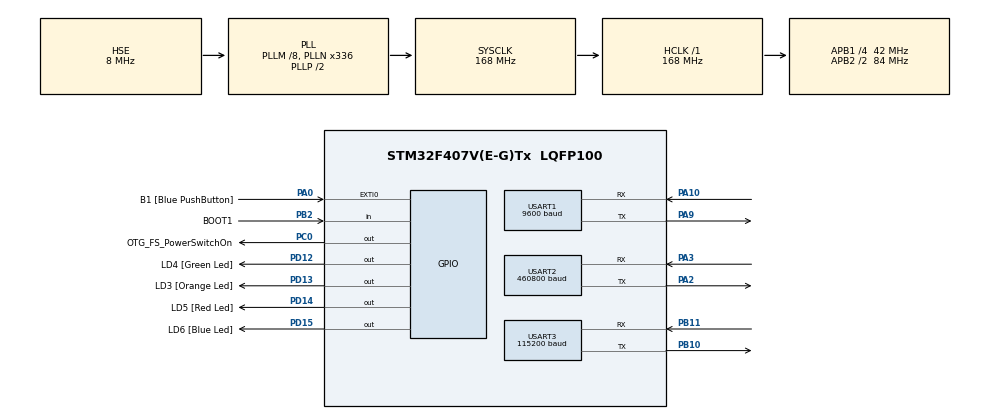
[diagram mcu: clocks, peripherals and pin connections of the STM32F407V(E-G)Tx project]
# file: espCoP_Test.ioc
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Dma.Request0=USART3_RX
Dma.Request1=USART3_TX
Dma.Request2=USART2_TX
Dma.Request3=USART1_RX
Dma.Request4=USART1_TX
Dma.USART1_RX.3.Direction=DMA_PERIPH_TO_MEMORY
Dma.USART1_RX.3.FIFOMode=DMA_FIFOMODE_DISABLE
Dma.USART1_RX.3.Instance=DMA2_Stream2
Dma.USART1_RX.3.MemDataAlignment=DMA_MDATAALIGN_BYTE
Dma.USART1_RX.3.MemInc=DMA_MINC_ENABLE
Dma.USART1_RX.3.Mode=DMA_NORMAL
Dma.USART1_RX.3.PeriphDataAlignment=DMA_PDATAALIGN_BYTE
Dma.USART1_RX.3.PeriphInc=DMA_PINC_DISABLE
Dma.USART1_RX.3.Priority=DMA_PRIORITY_LOW
Dma.USART1_TX.4.Direction=DMA_MEMORY_TO_PERIPH
Dma.USART1_TX.4.FIFOMode=DMA_FIFOMODE_DISABLE
Dma.USART1_TX.4.Instance=DMA2_Stream7
Dma.USART1_TX.4.MemDataAlignment=DMA_MDATAALIGN_BYTE
Dma.USART1_TX.4.MemInc=DMA_MINC_ENABLE
Dma.USART1_TX.4.Mode=DMA_NORMAL
Dma.USART1_TX.4.PeriphDataAlignment=DMA_PDATAALIGN_BYTE
Dma.USART1_TX.4.PeriphInc=DMA_PINC_DISABLE
Dma.USART1_TX.4.Priority=DMA_PRIORITY_LOW
Dma.USART2_TX.2.Direction=DMA_MEMORY_TO_PERIPH
Dma.USART2_TX.2.FIFOMode=DMA_FIFOMODE_DISABLE
Dma.USART2_TX.2.Instance=DMA1_Stream6
Dma.USART2_TX.2.MemDataAlignment=DMA_MDATAALIGN_BYTE
Dma.USART2_TX.2.MemInc=DMA_MINC_ENABLE
Dma.USART2_TX.2.Mode=DMA_NORMAL
Dma.USART2_TX.2.PeriphDataAlignment=DMA_PDATAALIGN_BYTE
Dma.USART2_TX.2.PeriphInc=DMA_PINC_DISABLE
Dma.USART2_TX.2.Priority=DMA_PRIORITY_LOW
Dma.USART3_RX.0.Direction=DMA_PERIPH_TO_MEMORY
Dma.USART3_RX.0.FIFOMode=DMA_FIFOMODE_DISABLE
Dma.USART3_RX.0.Instance=DMA1_Stream1
Dma.USART3_RX.0.MemDataAlignment=DMA_MDATAALIGN_BYTE
Dma.USART3_RX.0.MemInc=DMA_MINC_ENABLE
Dma.USART3_RX.0.Mode=DMA_NORMAL
Dma.USART3_RX.0.PeriphDataAlignment=DMA_PDATAALIGN_BYTE
Dma.USART3_RX.0.PeriphInc=DMA_PINC_DISABLE
Dma.USART3_RX.0.Priority=DMA_PRIORITY_LOW
Dma.USART3_TX.1.Direction=DMA_MEMORY_TO_PERIPH
Dma.USART3_TX.1.FIFOMode=DMA_FIFOMODE_DISABLE
Dma.USART3_TX.1.Instance=DMA1_Stream3
Dma.USART3_TX.1.MemDataAlignment=DMA_MDATAALIGN_BYTE
Dma.USART3_TX.1.MemInc=DMA_MINC_ENABLE
Dma.USART3_TX.1.Mode=DMA_NORMAL
Dma.USART3_TX.1.PeriphDataAlignment=DMA_PDATAALIGN_BYTE
Dma.USART3_TX.1.PeriphInc=DMA_PINC_DISABLE
Dma.USART3_TX.1.Priority=DMA_PRIORITY_LOW
Mcu.Family=STM32F4
Mcu.Name=STM32F407V(E-G)Tx
Mcu.Package=LQFP100
NVIC.DMA1_Stream1_IRQn=true\:0\:0\:false\:false\:true\:false
NVIC.DMA1_Stream3_IRQn=true\:0\:0\:false\:false\:true\:false
NVIC.DMA1_Stream6_IRQn=true\:0\:0\:false\:false\:true\:false
NVIC.DMA2_Stream2_IRQn=true\:0\:0\:false\:false\:true\:false
NVIC.DMA2_Stream7_IRQn=true\:0\:0\:false\:false\:true\:false
NVIC.PriorityGroup=NVIC_PRIORITYGROUP_0
NVIC.USART1_IRQn=true\:0\:0\:false\:false\:true\:true
NVIC.USART2_IRQn=true\:0\:0\:false\:false\:true\:true
NVIC.USART3_IRQn=true\:0\:0\:false\:false\:true\:true
PA0-WKUP.GPIO_Label=B1 [Blue PushButton]
PA0-WKUP.GPIO_ModeDefaultEXTI=GPIO_MODE_EVT_RISING
PA0-WKUP.GPIO_PuPd=GPIO_NOPULL
PA0-WKUP.Signal=GPXTI0
PA10.Mode=Asynchronous
PA10.Signal=USART1_RX
PA13.GPIO_Label=SWDIO
PA13.Mode=Serial_Wire
PA13.Signal=SYS_JTMS-SWDIO
PA14.GPIO_Label=SWCLK
PA14.Mode=Serial_Wire
PA14.Signal=SYS_JTCK-SWCLK
PA2.Mode=Asynchronous
PA2.Signal=USART2_TX
PA3.Mode=Asynchronous
PA3.Signal=USART2_RX
PA9.Mode=Asynchronous
PA9.Signal=USART1_TX
PB10.Mode=Asynchronous
PB10.Signal=USART3_TX
PB11.Mode=Asynchronous
PB11.Signal=USART3_RX
PB2.GPIO_Label=BOOT1
PB2.GPIO_Mode=GPIO_MODE_INPUT
PB2.GPIO_PuPd=GPIO_NOPULL
PB2.Signal=GPIO_Input
PB3.GPIO_Label=SWO
PB3.Signal=SYS_JTDO-SWO
PC0.GPIO_Label=OTG_FS_PowerSwitchOn
PC0.GPIO_PuPd=GPIO_NOPULL
PC0.GPIO_Speed=GPIO_SPEED_FREQ_LOW
PC0.PinState=GPIO_PIN_SET
PC0.Signal=GPIO_Output
PC14-OSC32_IN.GPIO_Label=PC14-OSC32_IN
PC14-OSC32_IN.Mode=LSE-External-Oscillator
PC14-OSC32_IN.Signal=RCC_OSC32_IN
PC15-OSC32_OUT.GPIO_Label=PC15-OSC32_OUT
PC15-OSC32_OUT.Mode=LSE-External-Oscillator
PC15-OSC32_OUT.Signal=RCC_OSC32_OUT
PC3.GPIO_Label=PDM_OUT [MP45DT02_DOUT]
PC3.GPIO_Mode=GPIO_MODE_AF_PP
PC3.GPIO_PuPd=GPIO_NOPULL
PC3.GPIO_Speed=GPIO_SPEED_FREQ_LOW
PC3.Signal=I2S2_SD
PD12.GPIO_Label=LD4 [Green Led]
PD12.GPIO_PuPd=GPIO_NOPULL
PD12.GPIO_Speed=GPIO_SPEED_FREQ_LOW
PD12.Signal=GPIO_Output
PD13.GPIO_Label=LD3 [Orange Led]
PD13.GPIO_PuPd=GPIO_NOPULL
PD13.GPIO_Speed=GPIO_SPEED_FREQ_LOW
PD13.Signal=GPIO_Output
PD14.GPIO_Label=LD5 [Red Led]
PD14.GPIO_PuPd=GPIO_NOPULL
PD14.GPIO_Speed=GPIO_SPEED_FREQ_LOW
PD14.Signal=GPIO_Output
PD15.GPIO_Label=LD6 [Blue Led]
PD15.GPIO_PuPd=GPIO_NOPULL
PD15.GPIO_Speed=GPIO_SPEED_FREQ_LOW
PD15.Signal=GPIO_Output
PH0-OSC_IN.GPIO_Label=PH0-OSC_IN
PH0-OSC_IN.Mode=HSE-External-Oscillator
PH0-OSC_IN.Signal=RCC_OSC_IN
PH1-OSC_OUT.GPIO_Label=PH1-OSC_OUT
PH1-OSC_OUT.Mode=HSE-External-Oscillator
PH1-OSC_OUT.Signal=RCC_OSC_OUT
ProjectManager.HeapSize=0x200
ProjectManager.StackSize=0x400
ProjectManager.TargetToolchain=TrueSTUDIO
RCC.48MHZClocksFreq_Value=48000000
RCC.AHBFreq_Value=168000000
RCC.APB1CLKDivider=RCC_HCLK_DIV4
RCC.APB1Freq_Value=42000000
RCC.APB1TimFreq_Value=84000000
RCC.APB2CLKDivider=RCC_HCLK_DIV2
RCC.APB2Freq_Value=84000000
RCC.APB2TimFreq_Value=168000000
RCC.CortexFreq_Value=168000000
RCC.HCLKFreq_Value=168000000
RCC.HSE_VALUE=8000000
RCC.HSI_VALUE=16000000
RCC.PLLM=8
RCC.PLLN=336
RCC.PLLQ=7
RCC.PLLSourceVirtual=RCC_PLLSOURCE_HSE
RCC.SYSCLKFreq_VALUE=168000000
RCC.SYSCLKSource=RCC_SYSCLKSOURCE_PLLCLK
RCC.VCOOutputFreq_Value=336000000
USART1.BaudRate=9600
USART1.VirtualMode=VM_ASYNC
USART2.BaudRate=460800
USART2.Mode=MODE_TX
USART2.VirtualMode=VM_ASYNC
USART3.BaudRate=115200
USART3.VirtualMode=VM_ASYNC
board=STM32F4DISCOVERY

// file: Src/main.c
/* USER CODE BEGIN Header */
/**
  ******************************************************************************
  * @file           : main.c
  * @brief          : Main program body
  ******************************************************************************
  ** This notice applies to any and all portions of this file
  * that are not between comment pairs USER CODE BEGIN and
  * USER CODE END. Other portions of this file, whether
  * inserted by the user or by software development tools
  * are owned by their respective copyright owners.
  *
  * COPYRIGHT(c) 2019 STMicroelectronics
  *
  * Redistribution and use in source and binary forms, with or without modification,
  * are permitted provided that the following conditions are met:
  *   1. Redistributions of source code must retain the above copyright notice,
  *      this list of conditions and the following disclaimer.
  *   2. Redistributions in binary form must reproduce the above copyright notice,
  *      this list of conditions and the following disclaimer in the documentation
  *      and/or other materials provided with the distribution.
  *   3. Neither the name of STMicroelectronics nor the names of its contributors
  *      may be used to endorse or promote products derived from this software
  *      without specific prior written permission.
  *
  * THIS SOFTWARE IS PROVIDED BY THE COPYRIGHT HOLDERS AND CONTRIBUTORS "AS IS"
  * AND ANY EXPRESS OR IMPLIED WARRANTIES, INCLUDING, BUT NOT LIMITED TO, THE
  * IMPLIED WARRANTIES OF MERCHANTABILITY AND FITNESS FOR A PARTICULAR PURPOSE ARE
  * DISCLAIMED. IN NO EVENT SHALL THE COPYRIGHT HOLDER OR CONTRIBUTORS BE LIABLE
  * FOR ANY DIRECT, INDIRECT, INCIDENTAL, SPECIAL, EXEMPLARY, OR CONSEQUENTIAL
  * DAMAGES (INCLUDING, BUT NOT LIMITED TO, PROCUREMENT OF SUBSTITUTE GOODS OR
  * SERVICES; LOSS OF USE, DATA, OR PROFITS; OR BUSINESS INTERRUPTION) HOWEVER
  * CAUSED AND ON ANY THEORY OF LIABILITY, WHETHER IN CONTRACT, STRICT LIABILITY,
  * OR TORT (INCLUDING NEGLIGENCE OR OTHERWISE) ARISING IN ANY WAY OUT OF THE USE
  * OF THIS SOFTWARE, EVEN IF ADVISED OF THE POSSIBILITY OF SUCH DAMAGE.
  *
  ******************************************************************************
  */
/* USER CODE END Header */

#include "main.h"
#include "dma.h"
#include "usart.h"
#include "gpio.h"

/* USER CODE BEGIN Includes */
#include <esp_basic.h>
#include <esp_wifi.h>
#include "debug.h"
#include "slre.h"
#include "assert.h"
//#include "qa_basic.h"
/* USER CODE END Includes */

/* USER CODE BEGIN PV */
//const char ssid[] = "HUAWEI-DUge\0";
//const char password[] = "485754439FED179D\0";
/* USER CODE END PV */

void SystemClock_Config(void);

int main(void)
{

  /* MCU Configuration--------------------------------------------------------*/

  /* Reset of all peripherals, Initializes the Flash interface and the Systick. */
  HAL_Init();

  /* Configure the system clock */
  SystemClock_Config();

  /* Initialize all configured peripherals */
  MX_GPIO_Init();
  MX_DMA_Init();
  MX_USART3_UART_Init();
  MX_USART2_UART_Init();
  MX_USART1_UART_Init();
  /* USER CODE BEGIN 2 */
  debug_init();
  /* USER CODE END 2 */

  /* Infinite loop */
  while (1)
  {
    /* USER CODE BEGIN 3 */
	  Test_EspBasicStack();
	  Test_EspWifiStack();
	  Test_EspTcpStack();
	  HAL_Delay(1000);
  }
  /* USER CODE END 3 */
}

void SystemClock_Config(void)
{
  RCC_OscInitTypeDef RCC_OscInitStruct = {0};
  RCC_ClkInitTypeDef RCC_ClkInitStruct = {0};

  /**Configure the main internal regulator output voltage
  */
  __HAL_RCC_PWR_CLK_ENABLE();
  __HAL_PWR_VOLTAGESCALING_CONFIG(PWR_REGULATOR_VOLTAGE_SCALE1);
  /**Initializes the CPU, AHB and APB busses clocks
  */
  RCC_OscInitStruct.OscillatorType = RCC_OSCILLATORTYPE_HSE;
  RCC_OscInitStruct.HSEState = RCC_HSE_ON;
  RCC_OscInitStruct.PLL.PLLState = RCC_PLL_ON;
  RCC_OscInitStruct.PLL.PLLSource = RCC_PLLSOURCE_HSE;
  RCC_OscInitStruct.PLL.PLLM = 8;
  RCC_OscInitStruct.PLL.PLLN = 336;
  RCC_OscInitStruct.PLL.PLLP = RCC_PLLP_DIV2;
  RCC_OscInitStruct.PLL.PLLQ = 7;
  if (HAL_RCC_OscConfig(&RCC_OscInitStruct) != HAL_OK)
  {
    Error_Handler();
  }
  /**Initializes the CPU, AHB and APB busses clocks
  */
  RCC_ClkInitStruct.ClockType = RCC_CLOCKTYPE_HCLK|RCC_CLOCKTYPE_SYSCLK
                              |RCC_CLOCKTYPE_PCLK1|RCC_CLOCKTYPE_PCLK2;
  RCC_ClkInitStruct.SYSCLKSource = RCC_SYSCLKSOURCE_PLLCLK;
  RCC_ClkInitStruct.AHBCLKDivider = RCC_SYSCLK_DIV1;
  RCC_ClkInitStruct.APB1CLKDivider = RCC_HCLK_DIV4;
  RCC_ClkInitStruct.APB2CLKDivider = RCC_HCLK_DIV2;

  if (HAL_RCC_ClockConfig(&RCC_ClkInitStruct, FLASH_LATENCY_5) != HAL_OK)
  {
    Error_Handler();
  }
}

void Error_Handler(void)
{
}

/************************ (C) COPYRIGHT STMicroelectronics *****END OF FILE****/
